# CW32L012 register map
Vendor: Wuhan Xinyuan Semiconductor Co.Ltd; Series: ARMCM0P; File version: 1.2
CPU: CM0+ r0p1, little endian, no MPU, no FPU, VTOR, 2 interrupt priority bits
Registers are 32-bit, read-write, no defined reset value unless marked. A register's access mark holds for its fields unless they carry their own. Offsets are from the block's base; [hi:lo] are bit positions; {n}, {i} and the like mark numbered series; 'fields as' and 'values as' point back to an identical list.

## LPTIM
Base 0x40006000
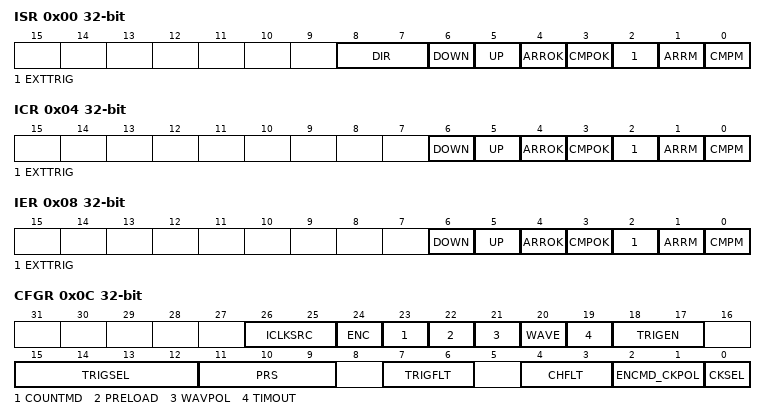
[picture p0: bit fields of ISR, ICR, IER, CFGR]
0x00 ISR ro
  [8:7] DIR, [6] DOWN, [5] UP, [4] ARROK, [3] CMPOK, [2] EXTTRIG, [1] ARRM, [0] CMPM
0x04 ICR
  [6] DOWN, [5] UP, [4] ARROK, [3] CMPOK, [2] EXTTRIG, [1] ARRM, [0] CMPM
0x08 IER
  fields as ICR
0x0C CFGR
  [26:25] ICLKSRC, [24] ENC, [23] COUNTMD, [22] PRELOAD, [21] WAVPOL, [20] WAVE, [19] TIMOUT, [18:17] TRIGEN, [15:12] TRIGSEL, [11:9] PRS, [7:6] TRIGFLT, [4:3] CHFLT, [2:1] ENCMD_CKPOL, [0] CKSEL
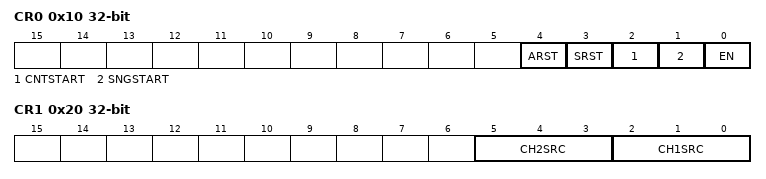
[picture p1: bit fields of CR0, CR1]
0x10 CR0
  [4] ARST, [3] SRST, [2] CNTSTART, [1] SNGSTART, [0] EN
0x14 CMP
  [15:0] CMP
0x18 ARR
  [15:0] ARR
0x1C CNT ro
  [15:0] CNT
0x20 CR1
  [5:3] CH2SRC, [2:0] CH1SRC

## LVD
Base 0x400000A4
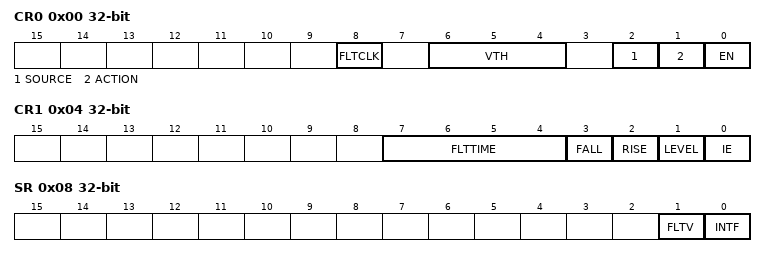
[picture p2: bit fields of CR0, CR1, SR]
0x00 CR0 — Control register0
  [8] FLTCLK, [6:4] VTH, [2] SOURCE, [1] ACTION, [0] EN
0x04 CR1 — Control register1
  [7:4] FLTTIME, [3] FALL, [2] RISE, [1] LEVEL, [0] IE
0x08 SR — status register
  [1] FLTV ro, [0] INTF

## OPA1
Base 0x400000B0
Same registers: OPA2 0x400000B8
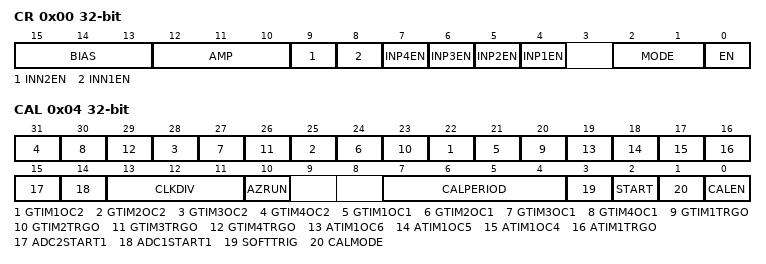
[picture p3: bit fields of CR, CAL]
0x00 CR
  [15:13] BIAS, [12:10] AMP, [9] INN2EN, [8] INN1EN, [n+3] INP{n}EN (n=1..4), [2:1] MODE, [0] EN
0x04 CAL
  [3n+19] GTIM{n}OC2 (n=1..4), [3n+18] GTIM{n}OC1 (n=1..4), [3n+17] GTIM{n}TRGO (n=1..4), [19] ATIM1OC6, [18] ATIM1OC5, [17] ATIM1OC4, [16] ATIM1TRGO, [15] ADC2START1, [14] ADC1START1, [13:11] CLKDIV, [10] AZRUN ro, [7:4] CALPERIOD, [3] SOFTTRIG, [2] START, [1] CALMODE, [0] CALEN

## RAM
Base 0x40022400
0x00 IER — Interrupt enable register
  [0] PARITY
0x04 ADDR ro — Error address register
0x08 ISR ro — Interrupt status register
  [0] PARITY
0x0C ICR — Interrupt flag clear register
  [0] PARITY

## RTC
Base 0x40004400
0x00 KEY wo
  [7:0] KEY
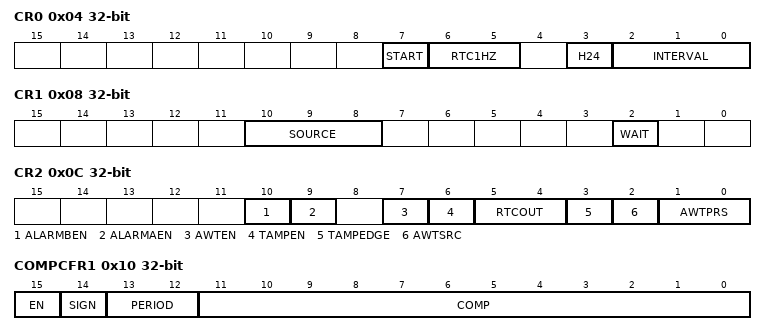
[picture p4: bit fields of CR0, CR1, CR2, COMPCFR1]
0x04 CR0
  [7] START, [6:5] RTC1HZ, [3] H24, [2:0] INTERVAL
0x08 CR1
  [10:8] SOURCE, [2] WAIT ro
0x0C CR2
  [10] ALARMBEN, [9] ALARMAEN, [7] AWTEN, [6] TAMPEN, [5:4] RTCOUT, [3] TAMPEDGE, [2] AWTSRC, [1:0] AWTPRS
0x10 COMPCFR1
  [15] EN, [14] SIGN, [13:12] PERIOD, [11:0] COMP
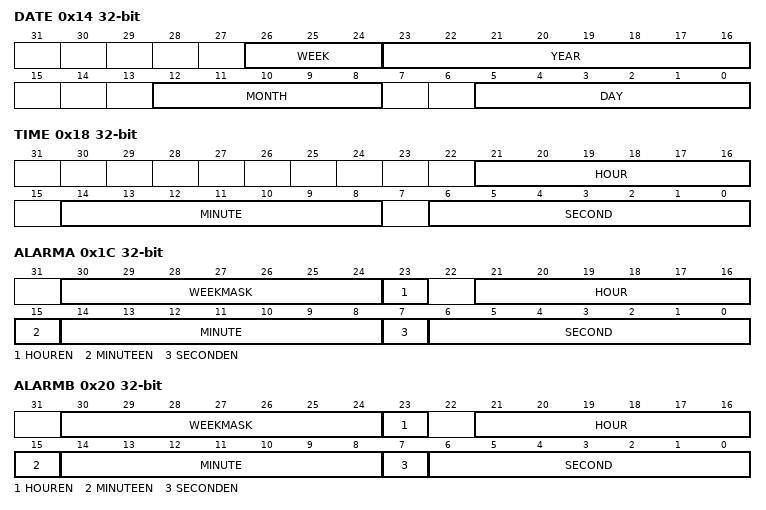
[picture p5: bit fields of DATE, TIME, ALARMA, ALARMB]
0x14 DATE
  [26:24] WEEK, [23:16] YEAR, [12:8] MONTH, [5:0] DAY
0x18 TIME
  [21:16] HOUR, [14:8] MINUTE, [6:0] SECOND
0x1C ALARMA
  [30:24] WEEKMASK, [23] HOUREN, [21:16] HOUR, [15] MINUTEEN, [14:8] MINUTE, [7] SECONDEN, [6:0] SECOND
0x20 ALARMB
  fields as ALARMA
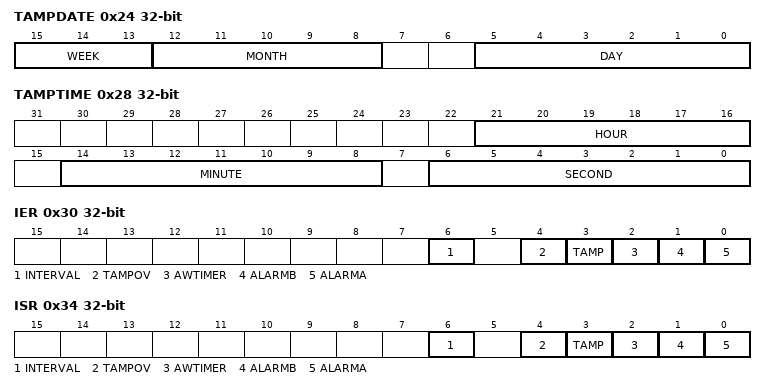
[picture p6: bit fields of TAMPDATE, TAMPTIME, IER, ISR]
0x24 TAMPDATE ro
  [15:13] WEEK, [12:8] MONTH, [5:0] DAY
0x28 TAMPTIME ro
  [21:16] HOUR, [14:8] MINUTE, [6:0] SECOND
0x2C AWTARR
  [15:0] ARR
0x30 IER
  [6] INTERVAL, [4] TAMPOV, [3] TAMP, [2] AWTIMER, [1] ALARMB, [0] ALARMA
0x34 ISR ro
  fields as IER
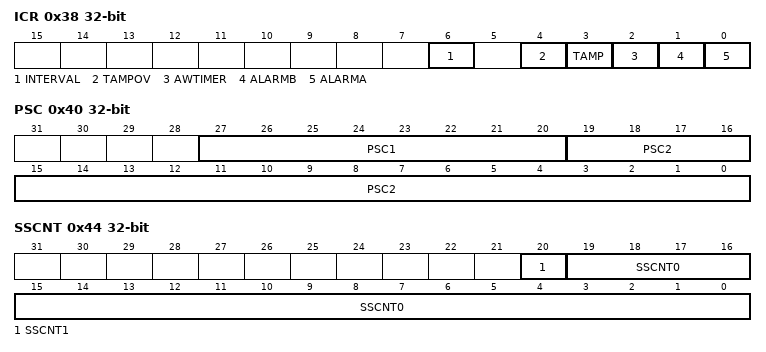
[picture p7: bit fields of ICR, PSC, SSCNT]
0x38 ICR
  fields as IER
0x3C AWTCNT ro
  [15:0] CNT
0x40 PSC
  [27:20] PSC1, [19:0] PSC2
0x44 SSCNT ro
  [20] SSCNT1, [19:0] SSCNT0

## SPI1
Base 0x40000800
Same registers: SPI2 0x40000400, SPI3 0x40003400
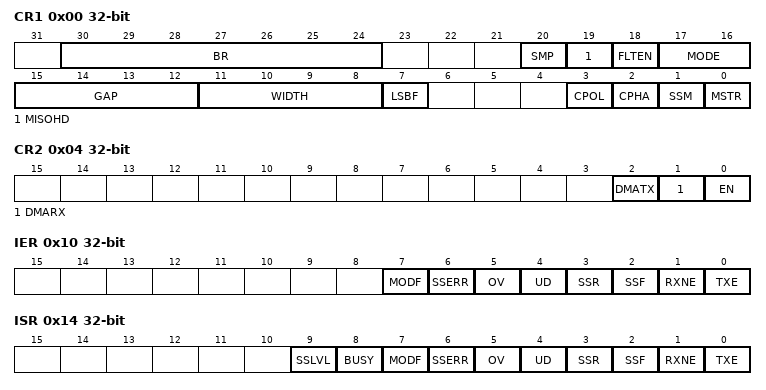
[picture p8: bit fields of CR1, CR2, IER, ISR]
0x00 CR1 — Control register1
  [30:24] BR, [20] SMP, [19] MISOHD, [18] FLTEN, [17:16] MODE, [15:12] GAP, [11:8] WIDTH, [7] LSBF, [3] CPOL, [2] CPHA, [1] SSM, [0] MSTR
0x04 CR2 — Control register2
  [2] DMATX, [1] DMARX, [0] EN
0x08 CR3
  [0] HDOE
0x0C SSI — Slave slect register
  [0] SSI
0x10 IER — Interrupt enable register
  [7] MODF, [6] SSERR, [5] OV, [4] UD, [3] SSR, [2] SSF, [1] RXNE, [0] TXE
0x14 ISR ro — Interrupt status register
  [9] SSLVL, [8] BUSY, [7] MODF, [6] SSERR, [5] OV, [4] UD, [3] SSR, [2] SSF, [1] RXNE, [0] TXE
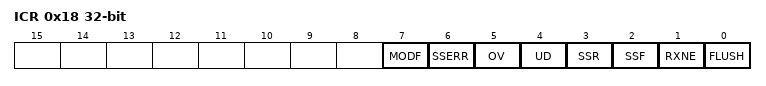
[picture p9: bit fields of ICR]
0x18 ICR — Interrupt flag clear register
  [7] MODF, [6] SSERR, [5] OV, [4] UD, [3] SSR, [2] SSF, [1] RXNE, [0] FLUSH
0x1C DR — Data register
  [15:0] DR

## SYSCTRL — System Ctrl
Base 0x40004000
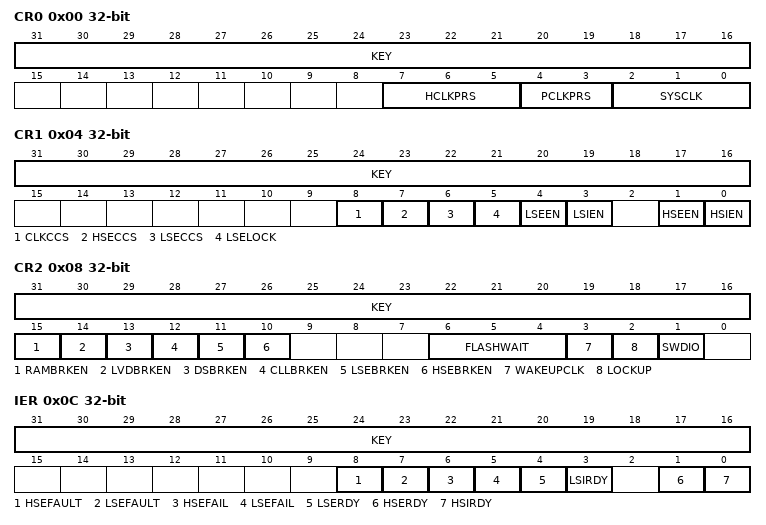
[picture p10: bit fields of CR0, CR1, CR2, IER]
0x00 CR0 — Control Reg0
  [31:16] KEY wo, [7:5] HCLKPRS, [4:3] PCLKPRS, [2:0] SYSCLK
0x04 CR1 — Control Reg1
  [31:16] KEY wo, [8] CLKCCS, [7] HSECCS, [6] LSECCS, [5] LSELOCK, [4] LSEEN, [3] LSIEN, [1] HSEEN, [0] HSIEN
0x08 CR2 — Control Reg2
  [31:16] KEY wo, [15] RAMBRKEN, [14] LVDBRKEN, [13] DSBRKEN, [12] CLLBRKEN, [11] LSEBRKEN, [10] HSEBRKEN, [6:4] FLASHWAIT, [3] WAKEUPCLK, [2] LOCKUP, [1] SWDIO
0x0C IER — Interupt Enable Reg
  [31:16] KEY wo, [8] HSEFAULT, [7] LSEFAULT, [6] HSEFAIL, [5] LSEFAIL, [4] LSERDY, [3] LSIRDY, [1] HSERDY, [0] HSIRDY
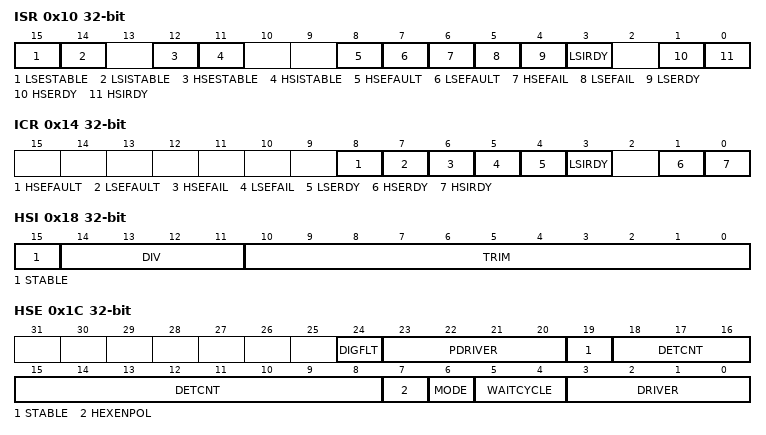
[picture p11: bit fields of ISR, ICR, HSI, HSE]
0x10 ISR ro — Interupt Status Reg
  [15] LSESTABLE, [14] LSISTABLE, [12] HSESTABLE, [11] HSISTABLE, [8] HSEFAULT, [7] LSEFAULT, [6] HSEFAIL, [5] LSEFAIL, [4] LSERDY, [3] LSIRDY, [1] HSERDY, [0] HSIRDY
0x14 ICR — Interupt Clear Reg
  [8] HSEFAULT, [7] LSEFAULT, [6] HSEFAIL, [5] LSEFAIL, [4] LSERDY, [3] LSIRDY, [1] HSERDY, [0] HSIRDY
0x18 HSI — HSI Control Reg
  [15] STABLE ro, [14:11] DIV, [10:0] TRIM
0x1C HSE
  [24] DIGFLT, [23:20] PDRIVER, [19] STABLE ro, [18:8] DETCNT, [7] HEXENPOL, [6] MODE, [5:4] WAITCYCLE, [3:0] DRIVER
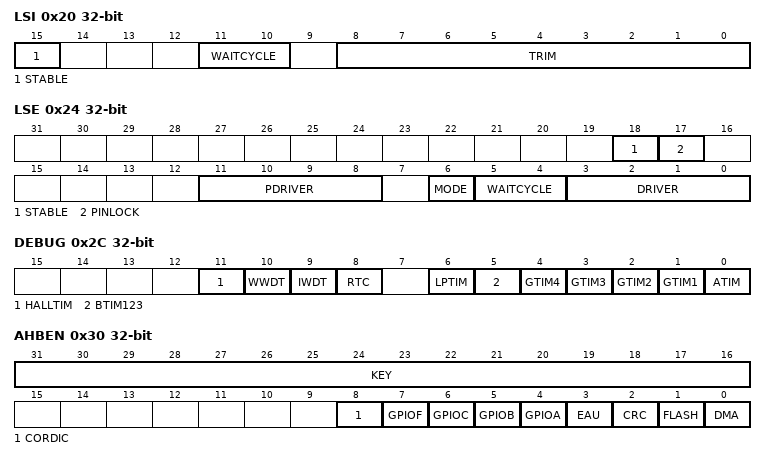
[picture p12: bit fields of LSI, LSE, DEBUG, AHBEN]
0x20 LSI — LSI Control Reg
  [15] STABLE ro, [11:10] WAITCYCLE, [8:0] TRIM
0x24 LSE — LSE Control Reg
  [18] STABLE ro, [17] PINLOCK, [11:8] PDRIVER, [6] MODE, [5:4] WAITCYCLE, [3:0] DRIVER
0x2C DEBUG — Debug Control Reg
  [11] HALLTIM, [10] WWDT, [9] IWDT, [8] RTC, [6] LPTIM, [5] BTIM123, [n] GTIM{n} (n=1..4), [0] ATIM
0x30 AHBEN — AHB Clock Control Reg
  [31:16] KEY wo, [8] CORDIC, [7] GPIOF, [6] GPIOC, [5] GPIOB, [4] GPIOA, [3] EAU, [2] CRC, [1] FLASH, [0] DMA
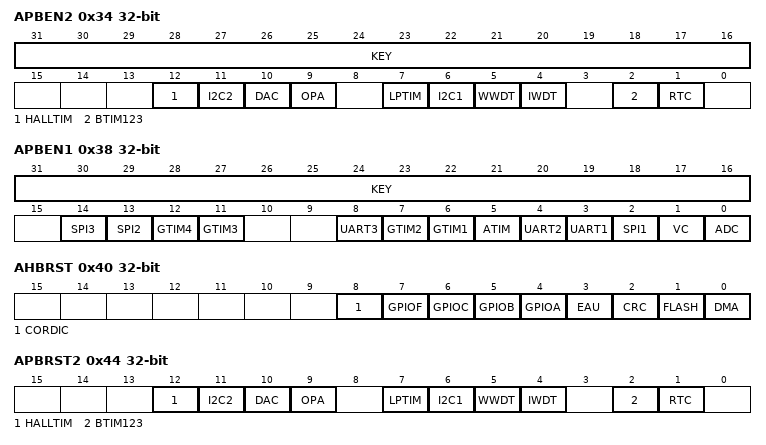
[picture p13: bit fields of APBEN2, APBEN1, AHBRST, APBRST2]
0x34 APBEN2 — APB Clock Control Reg2
  [31:16] KEY wo, [12] HALLTIM, [11] I2C2, [10] DAC, [9] OPA, [7] LPTIM, [6] I2C1, [5] WWDT, [4] IWDT, [2] BTIM123, [1] RTC
0x38 APBEN1 — APB Clock Control Reg1
  [31:16] KEY wo, [14] SPI3, [13] SPI2, [12] GTIM4, [11] GTIM3, [8] UART3, [7] GTIM2, [6] GTIM1, [5] ATIM, [4] UART2, [3] UART1, [2] SPI1, [1] VC, [0] ADC
0x40 AHBRST — AHB Reset Control Reg
  [8] CORDIC, [7] GPIOF, [6] GPIOC, [5] GPIOB, [4] GPIOA, [3] EAU, [2] CRC, [1] FLASH, [0] DMA
0x44 APBRST2 — APB Reset Control Reg2
  [12] HALLTIM, [11] I2C2, [10] DAC, [9] OPA, [7] LPTIM, [6] I2C1, [5] WWDT, [4] IWDT, [2] BTIM123, [1] RTC
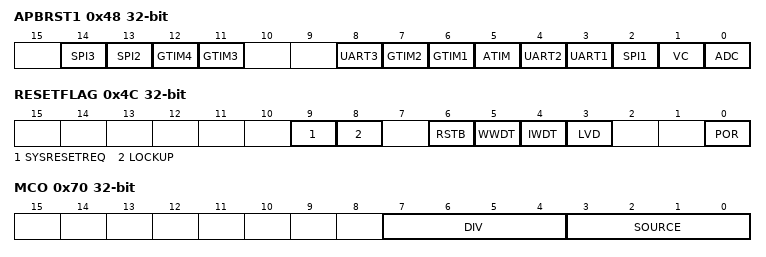
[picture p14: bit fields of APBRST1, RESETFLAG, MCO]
0x48 APBRST1 — APB Reset Control Reg1
  [14] SPI3, [13] SPI2, [12] GTIM4, [11] GTIM3, [8] UART3, [7] GTIM2, [6] GTIM1, [5] ATIM, [4] UART2, [3] UART1, [2] SPI1, [1] VC, [0] ADC
0x4C RESETFLAG — Reset Status Reg
  [9] SYSRESETREQ, [8] LOCKUP, [6] RSTB, [5] WWDT, [4] IWDT, [3] LVD, [0] POR
0x70 MCO — Master Clock Output Control Reg
  [7:4] DIV, [3:0] SOURCE

## UART1
Base 0x40000C00
Same registers: UART2 0x40001000, UART3 0x40002000
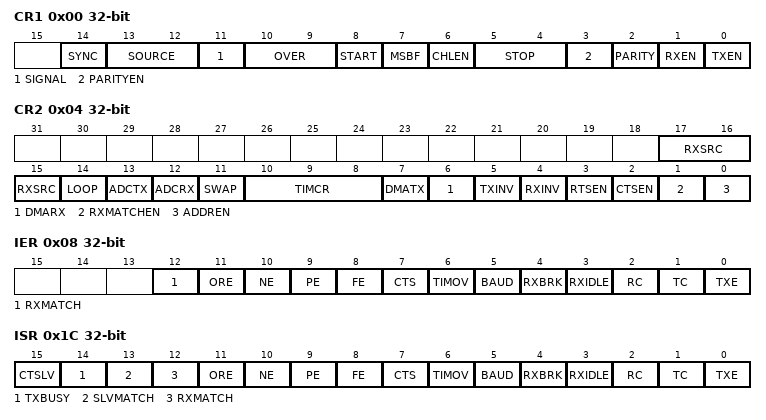
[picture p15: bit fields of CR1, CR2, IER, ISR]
0x00 CR1 — Control register1
  [14] SYNC, [13:12] SOURCE, [11] SIGNAL, [10:9] OVER, [8] START, [7] MSBF, [6] CHLEN, [5:4] STOP, [3] PARITYEN, [2] PARITY, [1] RXEN, [0] TXEN
0x04 CR2 — Control register2
  [17:15] RXSRC, [14] LOOP, [13] ADCTX, [12] ADCRX, [11] SWAP, [10:8] TIMCR, [7] DMATX, [6] DMARX, [5] TXINV, [4] RXINV, [3] RTSEN, [2] CTSEN, [1] RXMATCHEN, [0] ADDREN
0x08 IER — Interrupt enable register
  [12] RXMATCH, [11] ORE, [10] NE, [9] PE, [8] FE, [7] CTS, [6] TIMOV, [5] BAUD, [4] RXBRK, [3] RXIDLE, [2] RC, [1] TC, [0] TXE
0x0C BRRI
  [15:0] BRRI
0x10 BRRF
  [3:0] BRRF
0x14 TIMARR
  [23:0] TIMARR
0x18 TIMCNT ro
  [23:0] TIMCNT
0x1C ISR ro — Interrupt status register
  [15] CTSLV, [14] TXBUSY, [13] SLVMATCH, [12] RXMATCH, [11] ORE, [10] NE, [9] PE, [8] FE, [7] CTS, [6] TIMOV, [5] BAUD, [4] RXBRK, [3] RXIDLE, [2] RC, [1] TC, [0] TXE
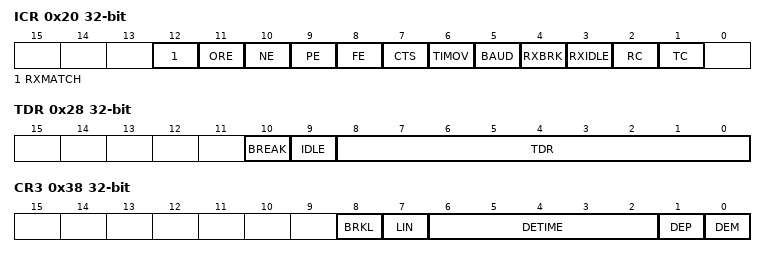
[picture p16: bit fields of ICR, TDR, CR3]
0x20 ICR — Interrupt flag clear register
  [12] RXMATCH, [11] ORE, [10] NE, [9] PE, [8] FE, [7] CTS, [6] TIMOV, [5] BAUD, [4] RXBRK, [3] RXIDLE, [2] RC, [1] TC
0x24 RDR ro — Data reg for read
  [8:0] RDR
0x28 TDR wo — Data reg for write
  [10] BREAK, [9] IDLE, [8:0] TDR
0x30 ADDR — Slave addr
  [7:0] ADDR
0x34 MASK — Slave addr mask
  [7:0] MASK
0x38 CR3 — Control register3
  [8] BRKL, [7] LIN, [6:2] DETIME, [1] DEP, [0] DEM
0x3C RXMATCH
  [8:0] RXMATCH

## VC1
Base 0x40000084
Same registers: VC2 0x40000094, VC3 0x40000184, VC4 0x40000194
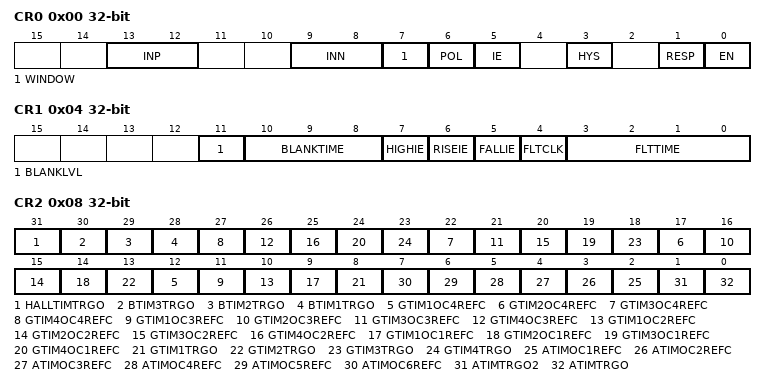
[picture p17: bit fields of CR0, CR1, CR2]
0x00 CR0 — Control register0
  [13:12] INP, [9:8] INN, [7] WINDOW, [6] POL, [5] IE, [3] HYS, [1] RESP, [0] EN
0x04 CR1 — Control register1
  [11] BLANKLVL, [10:8] BLANKTIME, [7] HIGHIE, [6] RISEIE, [5] FALLIE, [4] FLTCLK, [3:0] FLTTIME
0x08 CR2 — Control register1
  [31] HALLTIMTRGO — desc HALLTIM1TRGO
  [30] BTIM3TRGO
  [29] BTIM2TRGO
  [28] BTIM1TRGO
  [5n+7] GTIM{n}OC4REFC (n=1..4)
  [5n+6] GTIM{n}OC3REFC (n=1..4)
  [5n+5] GTIM{n}OC2REFC (n=1..4)
  [5n+4] GTIM{n}OC1REFC (n=1..4)
  [5n+3] GTIM{n}TRGO (n=1..4)
  [n+1] ATIMOC{n}REFC (n=1..6)
  [1] ATIMTRGO2
  [0] ATIMTRGO
0x0C SR — Status register
  [1] FLTV ro, [0] INTF

## VC12REF
Base 0x40000080
Same registers: VC34REF 0x40000180
0x00 REF — VCREF Control register
  [5] VIN, [4] EN, [2:0] DIV

## WWDT
Base 0x40005400
0x00 CR0 — Control register0
  [7] EN, [6:0] WCNT
0x04 CR1 — Control register1
  [10] IE
  [9:7] PRS — desc PRESCALE
  [6:0] WINR
0x08 SR — status register
  [0] POV
